AUTOSAR XML (schema 4-4-0)
package /EpsControl
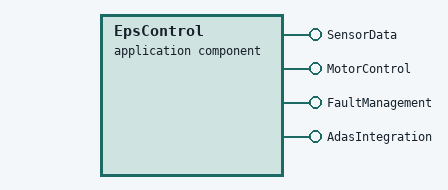
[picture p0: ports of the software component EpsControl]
  application software component type EpsControl: version=1.0.0  # Electric Power Steering Control Software Component
    4 x provide port:
      SensorData: client-server-com-spec=GetSensorData, client-server-com-spec=SetSensorData
      MotorControl: required-com-specs=[SetMotorCurrent, GetMotorStatus]
      FaultManagement: required-com-specs=[ReportFault, GetFaultStatus]
      AdasIntegration: sender-receiver-com-spec=AdasCommand, sender-receiver-com-spec=EpsStatus
    behavior EpsControl_InternalBehavior
      init event EpsControl_InitEvent: start-on-event=EpsControl_Init
      timing event EpsControl_PeriodicEvent: period=0.001, start-on-event=EpsControl_MainFunction
      4 x runnable:
        EpsControl_Init
        EpsControl_MainFunction
        EpsControl_CalculateAssistTorque
        EpsControl_FaultDetection
      data-type-mappings:
        application-data-type=float32, implementation-data-type=float32_impl
        application-data-type=uint32, implementation-data-type=uint32_impl
        application-data-type=boolean, implementation-data-type=boolean_impl
    swc implementation EpsControl_Implementation: behavior=EpsControl_InternalBehavior
      code-descriptors:
        code EpsControl.c: type=SRC
        code EpsControl.h: type=HDR
  client server interface SensorDataInterface
    operation GetSensorData: possible-error=SENSOR_DATA_ERROR
      argument sensorData: type=SensorData_t, direction=OUT
    operation SetSensorData
      argument sensorData: type=SensorData_t, direction=IN
  client server interface MotorControlInterface
    operation SetMotorCurrent: possible-error=MOTOR_CONTROL_ERROR
      argument targetCurrent: type=float32, direction=IN
    operation GetMotorStatus
      argument motorStatus: type=MotorStatus_t, direction=OUT
  client server interface FaultManagementInterface
    operation ReportFault
      argument faultCode: type=uint8, direction=IN
      argument faultLevel: type=uint8, direction=IN
      argument description: type=string, direction=IN
    operation GetFaultStatus
      argument faultStatus: type=FaultStatus_t, direction=OUT
  5 x app type, all with type-emitter=Platform:
    float32
    uint32
    uint8
    boolean
    string
  application record data type SensorData_t
    5 x application record element:
      driverTorque: type=float32
      steeringAngle: type=float32
      vehicleSpeed: type=float32
      dataValid: type=boolean
      timestamp: type=uint32
  application record data type MotorStatus_t
    5 x application record element:
      actualCurrent: type=float32
      motorVoltage: type=float32
      motorTemperature: type=float32
      motorEnabled: type=boolean
      faultDetected: type=boolean
  application record data type FaultStatus_t
    4 x application record element:
      faultCount: type=uint8
      faultLevel: type=uint8
      systemHealthy: type=boolean
      safeModeActive: type=boolean
  error SENSOR_DATA_ERROR: error-code=0x01
  error MOTOR_CONTROL_ERROR: error-code=0x02
